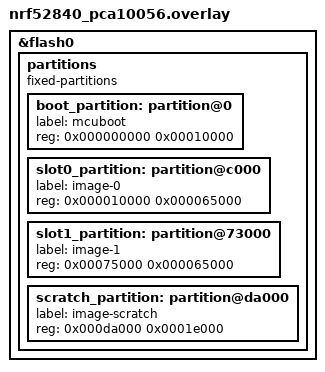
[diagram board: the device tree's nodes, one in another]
/*
 * Copyright (c) 2020 Nordic Semiconductor ASA
 *
 * SPDX-License-Identifier: Apache-2.0
 */

/delete-node/ &boot_partition;
/delete-node/ &slot0_partition;
/delete-node/ &slot1_partition;
/delete-node/ &scratch_partition;

&flash0 {
partitions {
		compatible = "fixed-partitions";
		#address-cells = <1>;
		#size-cells = <1>;

		boot_partition: partition@0 {
			label = "mcuboot";
			reg = <0x000000000 0x00010000>;
		};
		slot0_partition: partition@c000 {
			label = "image-0";
			reg = <0x000010000 0x000065000>;
		};
		slot1_partition: partition@73000 {
			label = "image-1";
			reg = <0x00075000 0x000065000>;
		};
		scratch_partition: partition@da000 {
			label = "image-scratch";
			reg = <0x000da000 0x0001e000>;
		};
};
};
